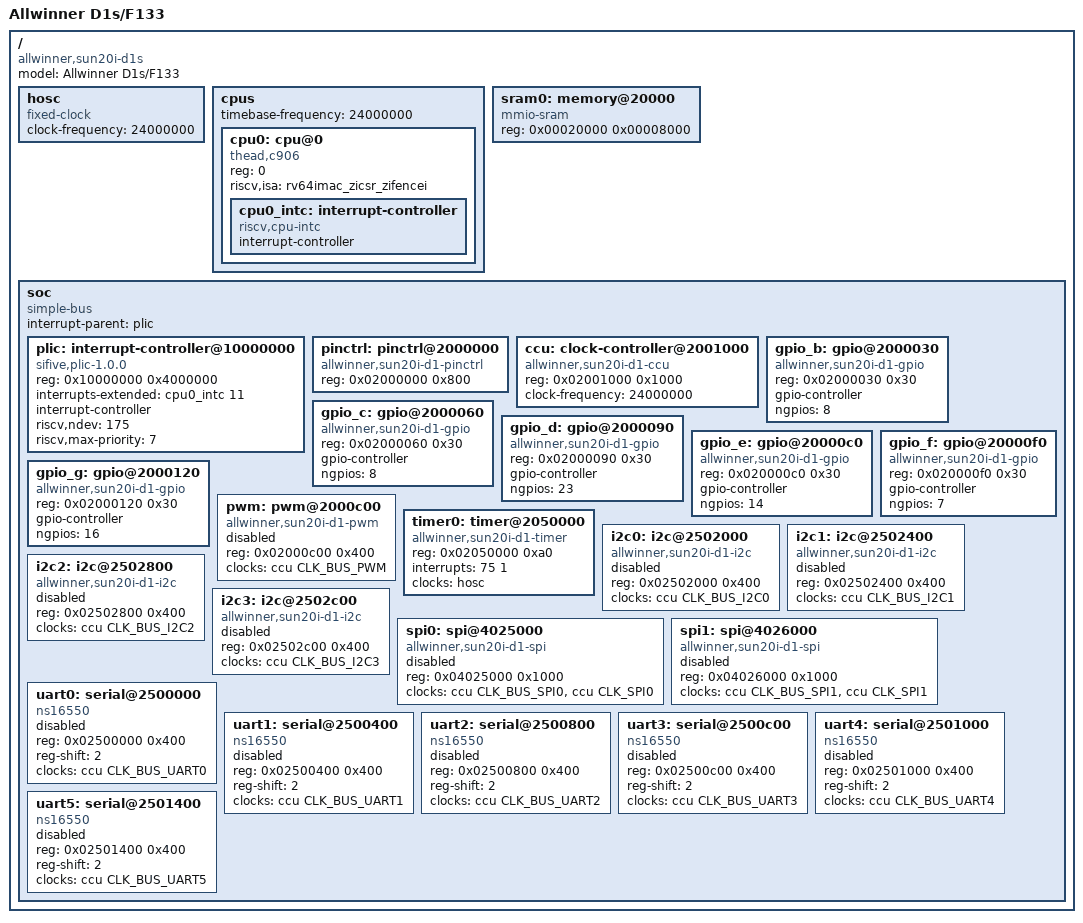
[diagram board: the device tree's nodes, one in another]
/*
 * Copyright (c) 2025
 *
 * SPDX-License-Identifier: Apache-2.0
 */

/dts-v1/;

#include <zephyr/dt-bindings/clock/allwinner-d1-ccu.h>

/ {
	#address-cells = <1>;
	#size-cells = <1>;
	compatible = "allwinner,sun20i-d1s";
	model = "Allwinner D1s/F133";

	hosc: hosc {
		compatible = "fixed-clock";
		#clock-cells = <0>;
		clock-frequency = <24000000>;
	};

	cpus {
		#address-cells = <1>;
		#size-cells = <0>;
		timebase-frequency = <24000000>;

		cpu0: cpu@0 {
			device_type = "cpu";
			reg = <0>;
			compatible = "thead,c906", "riscv";
			riscv,isa = "rv64imac_zicsr_zifencei";

			cpu0_intc: interrupt-controller {
				compatible = "riscv,cpu-intc";
				#address-cells = <0>;
				#interrupt-cells = <1>;
				interrupt-controller;
			};
		};
	};

	sram0: memory@20000 {
		device_type = "memory";
		compatible = "mmio-sram";
		reg = <0x00020000 0x00008000>;
	};

	soc {
		compatible = "simple-bus";
		#address-cells = <1>;
		#size-cells = <1>;
		ranges;
		interrupt-parent = <&plic>;

		plic: interrupt-controller@10000000 {
			compatible = "sifive,plic-1.0.0";
			#address-cells = <1>;
			reg = <0x10000000 0x4000000>;
			interrupts-extended = <&cpu0_intc 11>;
			interrupt-controller;
			riscv,ndev = <175>;
			riscv,max-priority = <7>;
			#interrupt-cells = <2>;
		};

		pinctrl: pinctrl@2000000 {
			compatible = "allwinner,sun20i-d1-pinctrl";
			reg = <0x02000000 0x800>;
			status = "okay";
		};

		ccu: clock-controller@2001000 {
			compatible = "allwinner,sun20i-d1-ccu";
			reg = <0x02001000 0x1000>;
			#clock-cells = <1>;
			clock-frequency = <24000000>;
			status = "okay";
		};

		gpio_b: gpio@2000030 {
			compatible = "allwinner,sun20i-d1-gpio";
			reg = <0x02000030 0x30>;
			gpio-controller;
			#gpio-cells = <2>;
			ngpios = <8>;
			status = "okay";
		};

		gpio_c: gpio@2000060 {
			compatible = "allwinner,sun20i-d1-gpio";
			reg = <0x02000060 0x30>;
			gpio-controller;
			#gpio-cells = <2>;
			ngpios = <8>;
			status = "okay";
		};

		gpio_d: gpio@2000090 {
			compatible = "allwinner,sun20i-d1-gpio";
			reg = <0x02000090 0x30>;
			gpio-controller;
			#gpio-cells = <2>;
			ngpios = <23>;
			status = "okay";
		};

		gpio_e: gpio@20000c0 {
			compatible = "allwinner,sun20i-d1-gpio";
			reg = <0x020000c0 0x30>;
			gpio-controller;
			#gpio-cells = <2>;
			ngpios = <14>;
			status = "okay";
		};

		gpio_f: gpio@20000f0 {
			compatible = "allwinner,sun20i-d1-gpio";
			reg = <0x020000f0 0x30>;
			gpio-controller;
			#gpio-cells = <2>;
			ngpios = <7>;
			status = "okay";
		};

		gpio_g: gpio@2000120 {
			compatible = "allwinner,sun20i-d1-gpio";
			reg = <0x02000120 0x30>;
			gpio-controller;
			#gpio-cells = <2>;
			ngpios = <16>;
			status = "okay";
		};

		pwm: pwm@2000c00 {
			compatible = "allwinner,sun20i-d1-pwm";
			reg = <0x02000c00 0x400>;
			clocks = <&ccu CLK_BUS_PWM>;
			#pwm-cells = <3>;
			status = "disabled";
		};

		timer0: timer@2050000 {
			compatible = "allwinner,sun20i-d1-timer",
				     "allwinner,sun8i-a23-timer";
			reg = <0x02050000 0xa0>;
			interrupts = <75 1>;
			clocks = <&hosc>;
			status = "okay";
		};

		i2c0: i2c@2502000 {
			compatible = "allwinner,sun20i-d1-i2c",
				     "allwinner,sun8i-v536-i2c",
				     "allwinner,sun6i-a31-i2c";
			reg = <0x02502000 0x400>;
			clocks = <&ccu CLK_BUS_I2C0>;
			#address-cells = <1>;
			#size-cells = <0>;
			status = "disabled";
		};

		i2c1: i2c@2502400 {
			compatible = "allwinner,sun20i-d1-i2c",
				     "allwinner,sun8i-v536-i2c",
				     "allwinner,sun6i-a31-i2c";
			reg = <0x02502400 0x400>;
			clocks = <&ccu CLK_BUS_I2C1>;
			#address-cells = <1>;
			#size-cells = <0>;
			status = "disabled";
		};

		i2c2: i2c@2502800 {
			compatible = "allwinner,sun20i-d1-i2c",
				     "allwinner,sun8i-v536-i2c",
				     "allwinner,sun6i-a31-i2c";
			reg = <0x02502800 0x400>;
			clocks = <&ccu CLK_BUS_I2C2>;
			#address-cells = <1>;
			#size-cells = <0>;
			status = "disabled";
		};

		i2c3: i2c@2502c00 {
			compatible = "allwinner,sun20i-d1-i2c",
				     "allwinner,sun8i-v536-i2c",
				     "allwinner,sun6i-a31-i2c";
			reg = <0x02502c00 0x400>;
			clocks = <&ccu CLK_BUS_I2C3>;
			#address-cells = <1>;
			#size-cells = <0>;
			status = "disabled";
		};

		spi0: spi@4025000 {
			compatible = "allwinner,sun20i-d1-spi",
				     "allwinner,sun50i-r329-spi";
			reg = <0x04025000 0x1000>;
			clocks = <&ccu CLK_BUS_SPI0>, <&ccu CLK_SPI0>;
			clock-names = "bus", "mod";
			#address-cells = <1>;
			#size-cells = <0>;
			status = "disabled";
		};

		spi1: spi@4026000 {
			compatible = "allwinner,sun20i-d1-spi",
				     "allwinner,sun50i-r329-spi";
			reg = <0x04026000 0x1000>;
			clocks = <&ccu CLK_BUS_SPI1>, <&ccu CLK_SPI1>;
			clock-names = "bus", "mod";
			#address-cells = <1>;
			#size-cells = <0>;
			status = "disabled";
		};

		uart0: serial@2500000 {
			compatible = "ns16550";
			reg = <0x02500000 0x400>;
			reg-shift = <2>;
			clocks = <&ccu CLK_BUS_UART0>;
			status = "disabled";
		};

		uart1: serial@2500400 {
			compatible = "ns16550";
			reg = <0x02500400 0x400>;
			reg-shift = <2>;
			clocks = <&ccu CLK_BUS_UART1>;
			status = "disabled";
		};

		uart2: serial@2500800 {
			compatible = "ns16550";
			reg = <0x02500800 0x400>;
			reg-shift = <2>;
			clocks = <&ccu CLK_BUS_UART2>;
			status = "disabled";
		};

		uart3: serial@2500c00 {
			compatible = "ns16550";
			reg = <0x02500c00 0x400>;
			reg-shift = <2>;
			clocks = <&ccu CLK_BUS_UART3>;
			status = "disabled";
		};

		uart4: serial@2501000 {
			compatible = "ns16550";
			reg = <0x02501000 0x400>;
			reg-shift = <2>;
			clocks = <&ccu CLK_BUS_UART4>;
			status = "disabled";
		};

		uart5: serial@2501400 {
			compatible = "ns16550";
			reg = <0x02501400 0x400>;
			reg-shift = <2>;
			clocks = <&ccu CLK_BUS_UART5>;
			status = "disabled";
		};
	};
};

#include "sun20i-d1s-pinctrl.dtsi"
